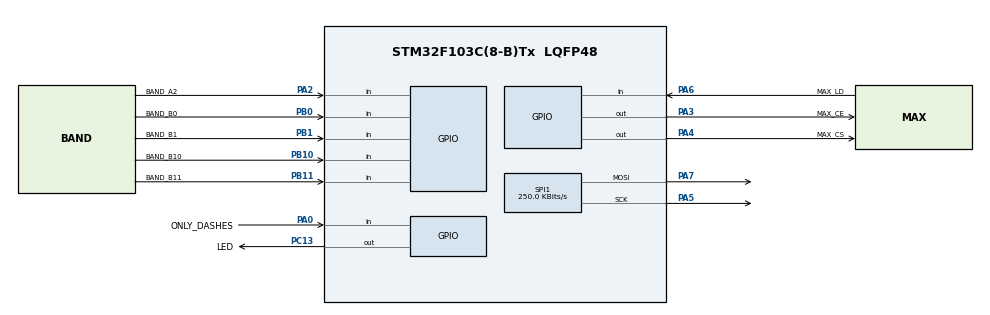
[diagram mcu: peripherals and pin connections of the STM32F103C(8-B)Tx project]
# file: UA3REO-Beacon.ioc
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Mcu.Family=STM32F1
Mcu.Name=STM32F103C(8-B)Tx
Mcu.Package=LQFP48
NVIC.PriorityGroup=NVIC_PRIORITYGROUP_4
PA0-WKUP.GPIO_Label=ONLY_DASHES
PA0-WKUP.GPIO_PuPd=GPIO_PULLUP
PA0-WKUP.Signal=GPIO_Input
PA2.GPIO_Label=BAND_A2
PA2.GPIO_PuPd=GPIO_PULLUP
PA2.Signal=GPIO_Input
PA3.GPIO_Label=MAX_CE
PA3.GPIO_PuPd=GPIO_PULLDOWN
PA3.Signal=GPIO_Output
PA4.GPIO_Label=MAX_CS
PA4.GPIO_PuPd=GPIO_PULLUP
PA4.Signal=GPIO_Output
PA5.Mode=TX_Only_Simplex_Unidirect_Master
PA5.Signal=SPI1_SCK
PA6.GPIO_Label=MAX_LD
PA6.GPIO_PuPd=GPIO_NOPULL
PA6.Signal=GPIO_Input
PA7.Mode=TX_Only_Simplex_Unidirect_Master
PA7.Signal=SPI1_MOSI
PB0.GPIO_Label=BAND_B0
PB0.GPIO_PuPd=GPIO_PULLUP
PB0.Signal=GPIO_Input
PB1.GPIO_Label=BAND_B1
PB1.GPIO_PuPd=GPIO_PULLUP
PB1.Signal=GPIO_Input
PB10.GPIO_Label=BAND_B10
PB10.GPIO_PuPd=GPIO_PULLUP
PB10.Signal=GPIO_Input
PB11.GPIO_Label=BAND_B11
PB11.GPIO_PuPd=GPIO_PULLUP
PB11.Signal=GPIO_Input
PC13-TAMPER-RTC.GPIO_Label=LED
PC13-TAMPER-RTC.GPIO_PuPd=GPIO_PULLUP
PC13-TAMPER-RTC.Signal=GPIO_Output
PC14-OSC32_IN.Mode=LSE-External-Oscillator
PC14-OSC32_IN.Signal=RCC_OSC32_IN
PC15-OSC32_OUT.Mode=LSE-External-Oscillator
PC15-OSC32_OUT.Signal=RCC_OSC32_OUT
PD0-OSC_IN.Mode=HSE-External-Oscillator
PD0-OSC_IN.Signal=RCC_OSC_IN
PD1-OSC_OUT.Mode=HSE-External-Oscillator
PD1-OSC_OUT.Signal=RCC_OSC_OUT
ProjectManager.HeapSize=0x0
ProjectManager.StackSize=0x400
ProjectManager.TargetToolchain=MDK-ARM V5.32
RCC.APB1Freq_Value=8000000
RCC.APB2Freq_Value=8000000
SPI1.BaudRatePrescaler=SPI_BAUDRATEPRESCALER_32
SPI1.CalculateBaudRate=250.0 KBits/s
SPI1.Direction=SPI_DIRECTION_2LINES
SPI1.Mode=SPI_MODE_MASTER
SPI1.VirtualType=VM_MASTER
VP_IWDG_VS_IWDG.Mode=IWDG_Activate
VP_SYS_VS_ND.Mode=No_Debug
board=custom

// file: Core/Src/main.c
/* USER CODE BEGIN Header */
/**
  ******************************************************************************
  * @file           : main.c
  * @brief          : Main program body
  ******************************************************************************
  * @attention
  *
  * Copyright (c) 2022 STMicroelectronics.
  * All rights reserved.
  *
  * This software is licensed under terms that can be found in the LICENSE file
  * in the root directory of this software component.
  * If no LICENSE file comes with this software, it is provided AS-IS.
  *
  ******************************************************************************
  */
/* USER CODE END Header */
#include "main.h"

/* USER CODE BEGIN Includes */
#include "transmitter.h"
/* USER CODE END Includes */

IWDG_HandleTypeDef hiwdg;

SPI_HandleTypeDef hspi1;

void SystemClock_Config(void);
static void MX_GPIO_Init(void);
static void MX_IWDG_Init(void);
static void MX_SPI1_Init(void);

int main(void)
{

  /* MCU Configuration--------------------------------------------------------*/

  /* Reset of all peripherals, Initializes the Flash interface and the Systick. */
  HAL_Init();

  /* Configure the system clock */
  SystemClock_Config();

  /* Initialize all configured peripherals */
  MX_GPIO_Init();
  MX_IWDG_Init();
  MX_SPI1_Init();
  /* USER CODE BEGIN 2 */
	TRANSMITTER_Init();
  /* USER CODE END 2 */

  /* Infinite loop */
  while (1)
  {

    /* USER CODE BEGIN 3 */
		TRANSMITTER_Process();
		__WFI();
  }
  /* USER CODE END 3 */
}

void SystemClock_Config(void)
{
  RCC_OscInitTypeDef RCC_OscInitStruct = {0};
  RCC_ClkInitTypeDef RCC_ClkInitStruct = {0};

  /** Initializes the RCC Oscillators according to the specified parameters
  * in the RCC_OscInitTypeDef structure.
  */
  RCC_OscInitStruct.OscillatorType = RCC_OSCILLATORTYPE_HSI|RCC_OSCILLATORTYPE_LSI;
  RCC_OscInitStruct.HSIState = RCC_HSI_ON;
  RCC_OscInitStruct.HSICalibrationValue = RCC_HSICALIBRATION_DEFAULT;
  RCC_OscInitStruct.LSIState = RCC_LSI_ON;
  RCC_OscInitStruct.PLL.PLLState = RCC_PLL_NONE;
  if (HAL_RCC_OscConfig(&RCC_OscInitStruct) != HAL_OK)
  {
    Error_Handler();
  }

  /** Initializes the CPU, AHB and APB buses clocks
  */
  RCC_ClkInitStruct.ClockType = RCC_CLOCKTYPE_HCLK|RCC_CLOCKTYPE_SYSCLK
                              |RCC_CLOCKTYPE_PCLK1|RCC_CLOCKTYPE_PCLK2;
  RCC_ClkInitStruct.SYSCLKSource = RCC_SYSCLKSOURCE_HSI;
  RCC_ClkInitStruct.AHBCLKDivider = RCC_SYSCLK_DIV1;
  RCC_ClkInitStruct.APB1CLKDivider = RCC_HCLK_DIV1;
  RCC_ClkInitStruct.APB2CLKDivider = RCC_HCLK_DIV1;

  if (HAL_RCC_ClockConfig(&RCC_ClkInitStruct, FLASH_LATENCY_0) != HAL_OK)
  {
    Error_Handler();
  }
}

static void MX_IWDG_Init(void)
{

  hiwdg.Instance = IWDG;
  hiwdg.Init.Prescaler = IWDG_PRESCALER_4;
  hiwdg.Init.Reload = 4095;
  if (HAL_IWDG_Init(&hiwdg) != HAL_OK)
  {
    Error_Handler();
  }

}

static void MX_SPI1_Init(void)
{

  /* SPI1 parameter configuration*/
  hspi1.Instance = SPI1;
  hspi1.Init.Mode = SPI_MODE_MASTER;
  hspi1.Init.Direction = SPI_DIRECTION_2LINES;
  hspi1.Init.DataSize = SPI_DATASIZE_8BIT;
  hspi1.Init.CLKPolarity = SPI_POLARITY_LOW;
  hspi1.Init.CLKPhase = SPI_PHASE_1EDGE;
  hspi1.Init.NSS = SPI_NSS_SOFT;
  hspi1.Init.BaudRatePrescaler = SPI_BAUDRATEPRESCALER_32;
  hspi1.Init.FirstBit = SPI_FIRSTBIT_MSB;
  hspi1.Init.TIMode = SPI_TIMODE_DISABLE;
  hspi1.Init.CRCCalculation = SPI_CRCCALCULATION_DISABLE;
  hspi1.Init.CRCPolynomial = 10;
  if (HAL_SPI_Init(&hspi1) != HAL_OK)
  {
    Error_Handler();
  }

}

static void MX_GPIO_Init(void)
{
  GPIO_InitTypeDef GPIO_InitStruct = {0};

  /* GPIO Ports Clock Enable */
  __HAL_RCC_GPIOC_CLK_ENABLE();
  __HAL_RCC_GPIOD_CLK_ENABLE();
  __HAL_RCC_GPIOA_CLK_ENABLE();
  __HAL_RCC_GPIOB_CLK_ENABLE();

  /*Configure GPIO pin Output Level */
  HAL_GPIO_WritePin(LED_GPIO_Port, LED_Pin, GPIO_PIN_RESET);

  /*Configure GPIO pin Output Level */
  HAL_GPIO_WritePin(GPIOA, MAX_CE_Pin|MAX_CS_Pin, GPIO_PIN_RESET);

  /*Configure GPIO pin : LED_Pin */
  GPIO_InitStruct.Pin = LED_Pin;
  GPIO_InitStruct.Mode = GPIO_MODE_OUTPUT_PP;
  GPIO_InitStruct.Pull = GPIO_PULLUP;
  GPIO_InitStruct.Speed = GPIO_SPEED_FREQ_LOW;
  HAL_GPIO_Init(LED_GPIO_Port, &GPIO_InitStruct);

  /*Configure GPIO pins : ONLY_DASHES_Pin BAND_A2_Pin */
  GPIO_InitStruct.Pin = ONLY_DASHES_Pin|BAND_A2_Pin;
  GPIO_InitStruct.Mode = GPIO_MODE_INPUT;
  GPIO_InitStruct.Pull = GPIO_PULLUP;
  HAL_GPIO_Init(GPIOA, &GPIO_InitStruct);

  /*Configure GPIO pin : MAX_CE_Pin */
  GPIO_InitStruct.Pin = MAX_CE_Pin;
  GPIO_InitStruct.Mode = GPIO_MODE_OUTPUT_PP;
  GPIO_InitStruct.Pull = GPIO_PULLDOWN;
  GPIO_InitStruct.Speed = GPIO_SPEED_FREQ_LOW;
  HAL_GPIO_Init(MAX_CE_GPIO_Port, &GPIO_InitStruct);

  /*Configure GPIO pin : MAX_CS_Pin */
  GPIO_InitStruct.Pin = MAX_CS_Pin;
  GPIO_InitStruct.Mode = GPIO_MODE_OUTPUT_PP;
  GPIO_InitStruct.Pull = GPIO_PULLUP;
  GPIO_InitStruct.Speed = GPIO_SPEED_FREQ_LOW;
  HAL_GPIO_Init(MAX_CS_GPIO_Port, &GPIO_InitStruct);

  /*Configure GPIO pin : MAX_LD_Pin */
  GPIO_InitStruct.Pin = MAX_LD_Pin;
  GPIO_InitStruct.Mode = GPIO_MODE_INPUT;
  GPIO_InitStruct.Pull = GPIO_NOPULL;
  HAL_GPIO_Init(MAX_LD_GPIO_Port, &GPIO_InitStruct);

  /*Configure GPIO pins : BAND_B0_Pin BAND_B1_Pin BAND_B10_Pin BAND_B11_Pin */
  GPIO_InitStruct.Pin = BAND_B0_Pin|BAND_B1_Pin|BAND_B10_Pin|BAND_B11_Pin;
  GPIO_InitStruct.Mode = GPIO_MODE_INPUT;
  GPIO_InitStruct.Pull = GPIO_PULLUP;
  HAL_GPIO_Init(GPIOB, &GPIO_InitStruct);

}

void Error_Handler(void)
{
  __disable_irq();
  while (1)
  {
  }
}
